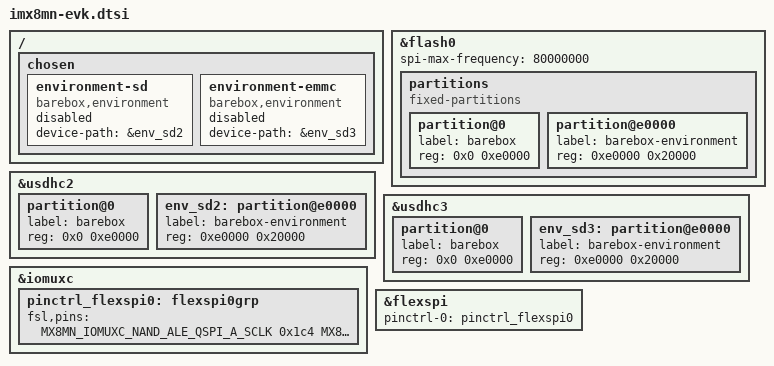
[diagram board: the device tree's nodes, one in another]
// SPDX-License-Identifier: (GPL-2.0 OR MIT)
/*
 * Copyright 2017 NXP
 * Copyright (C) 2017 Pengutronix, Lucas Stach <kernel@pengutronix.de>
 */

#include "imx8mn.dtsi"

/ {
	chosen {
		environment-sd {
			compatible = "barebox,environment";
			device-path = &env_sd2;
			status = "disabled";
		};
		environment-emmc {
			compatible = "barebox,environment";
			device-path = &env_sd3;
			status = "disabled";
		};
	};
};

&flash0 {
	partitions {
		compatible = "fixed-partitions";
		#address-cells = <1>;
		#size-cells = <1>;

		partition@0 {
			label = "barebox";
			reg = <0x0 0xe0000>;
		};

		partition@e0000 {
			label = "barebox-environment";
			reg = <0xe0000 0x20000>;
		};
	};

};

&usdhc2 {
	#address-cells = <1>;
	#size-cells = <1>;

	partition@0 {
		label = "barebox";
		reg = <0x0 0xe0000>;
	};

	env_sd2: partition@e0000 {
		label = "barebox-environment";
		reg = <0xe0000 0x20000>;
	};
};

&usdhc3 {
	#address-cells = <1>;
	#size-cells = <1>;

	partition@0 {
		label = "barebox";
		reg = <0x0 0xe0000>;
	};

	env_sd3: partition@e0000 {
		label = "barebox-environment";
		reg = <0xe0000 0x20000>;
	};
};

&iomuxc {
	pinctrl_flexspi0: flexspi0grp {
		fsl,pins = <
		MX8MN_IOMUXC_NAND_ALE_QSPI_A_SCLK	0x1c4
		MX8MN_IOMUXC_NAND_CE0_B_QSPI_A_SS0_B	0x84
		MX8MN_IOMUXC_NAND_DATA00_QSPI_A_DATA0	0x84
		MX8MN_IOMUXC_NAND_DATA01_QSPI_A_DATA1	0x84
		MX8MN_IOMUXC_NAND_DATA02_QSPI_A_DATA2	0x84
		MX8MN_IOMUXC_NAND_DATA03_QSPI_A_DATA3	0x84
		>;
	};
};

&flexspi {
	pinctrl-0 = <&pinctrl_flexspi0>;
};

&flash0 {
	spi-max-frequency = <80000000>;
};
